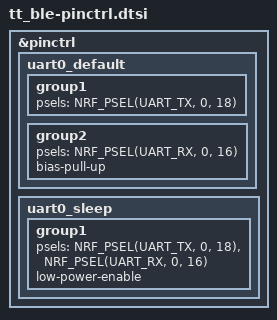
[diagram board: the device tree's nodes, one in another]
/*
 * TimeTaker BLE bridge pin control.
 *
 * The UART net names are the STM's view: UART1_TX (STM PB6) is the nRF's RX,
 * UART1_RX (STM PB7) is the nRF's TX. BLE_FIRMWARE_GUIDE.md §3.2.
 */

&pinctrl {
	uart0_default: uart0_default {
		group1 {
			psels = <NRF_PSEL(UART_TX, 0, 18)>;
		};
		group2 {
			psels = <NRF_PSEL(UART_RX, 0, 16)>;
			/* Keeps the line idle while the STM is in reset. */
			bias-pull-up;
		};
	};

	uart0_sleep: uart0_sleep {
		group1 {
			psels = <NRF_PSEL(UART_TX, 0, 18)>,
				<NRF_PSEL(UART_RX, 0, 16)>;
			low-power-enable;
		};
	};
};
